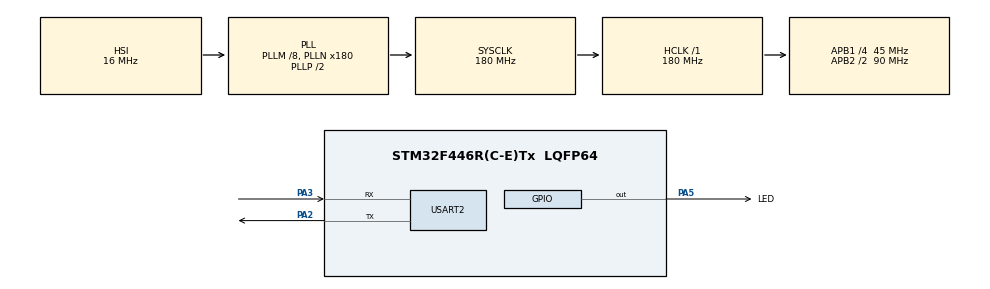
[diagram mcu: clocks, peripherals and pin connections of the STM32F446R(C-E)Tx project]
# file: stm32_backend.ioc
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FREERTOS.Tasks01=heartBeat,-2,128,StartHeartBeat,Default,NULL,Dynamic,NULL,NULL;dbgConsole,-2,128,dbgConsoleEntry,Default,NULL,Dynamic,NULL,NULL
Mcu.Family=STM32F4
Mcu.Name=STM32F446R(C-E)Tx
Mcu.Package=LQFP64
NVIC.PriorityGroup=NVIC_PRIORITYGROUP_4
NVIC.TIM1_UP_TIM10_IRQn=true\:0\:0\:false\:false\:true\:false\:false\:true
NVIC.TimeBase=TIM1_UP_TIM10_IRQn
NVIC.TimeBaseIP=TIM1
PA13.Mode=Serial_Wire
PA13.Signal=SYS_JTMS-SWDIO
PA14.Mode=Serial_Wire
PA14.Signal=SYS_JTCK-SWCLK
PA2.Mode=Asynchronous
PA2.Signal=USART2_TX
PA3.Mode=Asynchronous
PA3.Signal=USART2_RX
PA5.GPIO_Label=LED
PA5.Signal=GPIO_Output
PH0-OSC_IN.Mode=HSE-External-Oscillator
PH0-OSC_IN.Signal=RCC_OSC_IN
PH1-OSC_OUT.Mode=HSE-External-Oscillator
PH1-OSC_OUT.Signal=RCC_OSC_OUT
ProjectManager.HeapSize=0x200
ProjectManager.StackSize=0x400
ProjectManager.TargetToolchain=Makefile
RCC.AHBFreq_Value=180000000
RCC.APB1CLKDivider=RCC_HCLK_DIV4
RCC.APB1Freq_Value=45000000
RCC.APB1TimFreq_Value=90000000
RCC.APB2CLKDivider=RCC_HCLK_DIV2
RCC.APB2Freq_Value=90000000
RCC.APB2TimFreq_Value=180000000
RCC.CortexFreq_Value=180000000
RCC.FLatency-AdvancedSettings=FLASH_LATENCY_5
RCC.HCLKFreq_Value=180000000
RCC.HSE_VALUE=8000000
RCC.HSI_VALUE=16000000
RCC.LSE_VALUE=32768
RCC.PLLM=8
RCC.PLLN=180
RCC.SYSCLKFreq_VALUE=180000000
RCC.SYSCLKSource=RCC_SYSCLKSOURCE_PLLCLK
RCC.USBFreq_Value=180000000
RCC.VCOOutputFreq_Value=360000000
USART2.VirtualMode=VM_ASYNC
VP_FREERTOS_VS_CMSIS_V1.Mode=CMSIS_V1
VP_SYS_VS_tim1.Mode=TIM1
board=NUCLEO-F446RE

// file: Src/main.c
/* USER CODE BEGIN Header */
/**
 ******************************************************************************
 * @file           : main.c
 * @brief          : Main program body
 ******************************************************************************
 * @attention
 *
 * <h2><center>&copy; Copyright (c) 2019 STMicroelectronics.
 * All rights reserved.</center></h2>
 *
 * This software component is licensed by ST under BSD 3-Clause license,
 * the "License"; You may not use this file except in compliance with the
 * License. You may obtain a copy of the License at:
 *                        opensource.org/licenses/BSD-3-Clause
 *
 ******************************************************************************
 */
/* USER CODE END Header */

#include "main.h"
#include "cmsis_os.h"

/* USER CODE BEGIN Includes */
#include <string.h>
#include "drv_common_status.h"
#include "drv_logger.h"
#include "stdio.h"
/* USER CODE END Includes */

UART_HandleTypeDef huart2;

osThreadId heartBeatHandle;
osThreadId dbgConsoleHandle;

void SystemClock_Config(void);
static void MX_GPIO_Init(void);
static void MX_USART2_UART_Init(void);
void StartHeartBeat(void const * argument);
void dbgConsoleEntry(void const * argument);

int main(void)
{
  /* USER CODE BEGIN 1 */
	// uint8_t buff[50] = {0U};
  /* USER CODE END 1 */

  /* MCU Configuration--------------------------------------------------------*/

  /* Reset of all peripherals, Initializes the Flash interface and the Systick. */
  HAL_Init();

  /* Configure the system clock */
  SystemClock_Config();

  /* Initialize all configured peripherals */
  MX_GPIO_Init();
  MX_USART2_UART_Init();

  /* Create the thread(s) */
  /* definition and creation of heartBeat */
  osThreadDef(heartBeat, StartHeartBeat, osPriorityLow, 0, 128);
  heartBeatHandle = osThreadCreate(osThread(heartBeat), NULL);

  /* definition and creation of dbgConsole */
  osThreadDef(dbgConsole, dbgConsoleEntry, osPriorityLow, 0, 128);
  dbgConsoleHandle = osThreadCreate(osThread(dbgConsole), NULL);

  /* Start scheduler */
  osKernelStart();

  /* We should never get here as control is now taken by the scheduler */

  /* Infinite loop */
	while (1) {

	}
}

void SystemClock_Config(void)
{
  RCC_OscInitTypeDef RCC_OscInitStruct = {0};
  RCC_ClkInitTypeDef RCC_ClkInitStruct = {0};

  /** Configure the main internal regulator output voltage
  */
  __HAL_RCC_PWR_CLK_ENABLE();
  __HAL_PWR_VOLTAGESCALING_CONFIG(PWR_REGULATOR_VOLTAGE_SCALE1);
  /** Initializes the CPU, AHB and APB busses clocks
  */
  RCC_OscInitStruct.OscillatorType = RCC_OSCILLATORTYPE_HSI;
  RCC_OscInitStruct.HSIState = RCC_HSI_ON;
  RCC_OscInitStruct.HSICalibrationValue = RCC_HSICALIBRATION_DEFAULT;
  RCC_OscInitStruct.PLL.PLLState = RCC_PLL_ON;
  RCC_OscInitStruct.PLL.PLLSource = RCC_PLLSOURCE_HSI;
  RCC_OscInitStruct.PLL.PLLM = 8;
  RCC_OscInitStruct.PLL.PLLN = 180;
  RCC_OscInitStruct.PLL.PLLP = RCC_PLLP_DIV2;
  RCC_OscInitStruct.PLL.PLLQ = 2;
  RCC_OscInitStruct.PLL.PLLR = 2;
  if (HAL_RCC_OscConfig(&RCC_OscInitStruct) != HAL_OK)
  {
    Error_Handler();
  }
  /** Activate the Over-Drive mode
  */
  if (HAL_PWREx_EnableOverDrive() != HAL_OK)
  {
    Error_Handler();
  }
  /** Initializes the CPU, AHB and APB busses clocks
  */
  RCC_ClkInitStruct.ClockType = RCC_CLOCKTYPE_HCLK|RCC_CLOCKTYPE_SYSCLK
                              |RCC_CLOCKTYPE_PCLK1|RCC_CLOCKTYPE_PCLK2;
  RCC_ClkInitStruct.SYSCLKSource = RCC_SYSCLKSOURCE_PLLCLK;
  RCC_ClkInitStruct.AHBCLKDivider = RCC_SYSCLK_DIV1;
  RCC_ClkInitStruct.APB1CLKDivider = RCC_HCLK_DIV4;
  RCC_ClkInitStruct.APB2CLKDivider = RCC_HCLK_DIV2;

  if (HAL_RCC_ClockConfig(&RCC_ClkInitStruct, FLASH_LATENCY_5) != HAL_OK)
  {
    Error_Handler();
  }
}

static void MX_USART2_UART_Init(void)
{

  huart2.Instance = USART2;
  huart2.Init.BaudRate = 115200;
  huart2.Init.WordLength = UART_WORDLENGTH_8B;
  huart2.Init.StopBits = UART_STOPBITS_1;
  huart2.Init.Parity = UART_PARITY_NONE;
  huart2.Init.Mode = UART_MODE_TX_RX;
  huart2.Init.HwFlowCtl = UART_HWCONTROL_NONE;
  huart2.Init.OverSampling = UART_OVERSAMPLING_16;
  if (HAL_UART_Init(&huart2) != HAL_OK)
  {
    Error_Handler();
  }

}

static void MX_GPIO_Init(void)
{
  GPIO_InitTypeDef GPIO_InitStruct = {0};

  /* GPIO Ports Clock Enable */
  __HAL_RCC_GPIOH_CLK_ENABLE();
  __HAL_RCC_GPIOA_CLK_ENABLE();

  /*Configure GPIO pin Output Level */
  HAL_GPIO_WritePin(LED_GPIO_Port, LED_Pin, GPIO_PIN_RESET);

  /*Configure GPIO pin : LED_Pin */
  GPIO_InitStruct.Pin = LED_Pin;
  GPIO_InitStruct.Mode = GPIO_MODE_OUTPUT_PP;
  GPIO_InitStruct.Pull = GPIO_NOPULL;
  GPIO_InitStruct.Speed = GPIO_SPEED_FREQ_LOW;
  HAL_GPIO_Init(LED_GPIO_Port, &GPIO_InitStruct);

}

void StartHeartBeat(void const * argument)
{
  /* USER CODE BEGIN 5 */
	/* Infinite loop */
	for (;;) {
		HAL_GPIO_WritePin(LED_GPIO_Port, LED_Pin, GPIO_PIN_SET);
		osDelay(1000);
		HAL_GPIO_WritePin(LED_GPIO_Port, LED_Pin, GPIO_PIN_RESET);
		osDelay(1000);
	}
  /* USER CODE END 5 */
}

void dbgConsoleEntry(void const * argument)
{
  /* USER CODE BEGIN dbgConsoleEntry */
  /* Infinite loop */
  for(;;)
  {

		drv_logger_print(LOG_INFO, "afsad %d %d", 20, 15);
    osDelay(100);
  }
  /* USER CODE END dbgConsoleEntry */
}

void HAL_TIM_PeriodElapsedCallback(TIM_HandleTypeDef *htim)
{
  if (htim->Instance == TIM1) {
    HAL_IncTick();
  }
}

void Error_Handler(void)
{
  /* USER CODE BEGIN Error_Handler_Debug */
	/* User can add his own implementation to report the HAL error return state
	 */

  /* USER CODE END Error_Handler_Debug */
}

#ifdef  USE_FULL_ASSERT
/**
  * @brief  Reports the name of the source file and the source line number
  *         where the assert_param error has occurred.
  * @param  file: pointer to the source file name
  * @param  line: assert_param error line source number
  * @retval None
  */
void assert_failed(uint8_t *file, uint32_t line)
{
  /* USER CODE BEGIN 6 */
	/* User can add his own implementation to report the file name and line
		 number,
		 tex: printf("Wrong parameters value: file %s on line %d\r\n", file,
	   line)
	 */
  /* USER CODE END 6 */
}
#endif /* USE_FULL_ASSERT */

/************************ (C) COPYRIGHT STMicroelectronics *****END OF FILE****/
